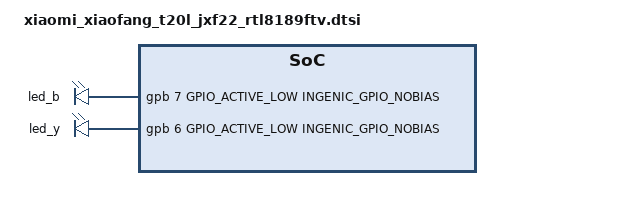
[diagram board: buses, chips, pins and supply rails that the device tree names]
// Xiaomi Xiaofang iSC5 (T20L, JXF22, RTL8189FTV) per-board GPIO definitions.
// Injected into the kernel 4.4+ device tree; ignored on 3.10.

#include <dt-bindings/gpio/gpio.h>
#include <dt-bindings/pinctrl/ingenic-pinctrl.h>

/ {
	gpio-leds {
		compatible = "gpio-leds";

		led_b {
			label = "led_b";
			gpios = <&gpb 7 GPIO_ACTIVE_LOW INGENIC_GPIO_NOBIAS>;
			default-state = "off";
		};

		led_y {
			label = "led_y";
			gpios = <&gpb 6 GPIO_ACTIVE_LOW INGENIC_GPIO_NOBIAS>;
			default-state = "off";
		};
	};
};

/* Card detect; the family tree carries the reference pin. */
&msc0 {
	ingenic,cd-gpios = <&gpb 11 GPIO_ACTIVE_LOW INGENIC_GPIO_PULLUP>;
};
